AUTOSAR XML (schema 00046)
package /MICROSAR/IoHwAb_swc/ComponentTypes
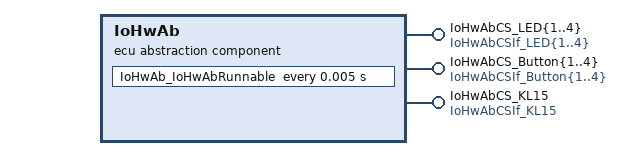
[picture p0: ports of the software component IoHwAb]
  ecu abstraction sw component type IoHwAb
    9 x provide port:
      IoHwAbCS_LED{1..4}: provided-interface=IoHwAbCSIf_LED{1..4}
      IoHwAbCS_Button{1..4}: provided-interface=IoHwAbCSIf_Button{1..4}
      IoHwAbCS_KL15: provided-interface=IoHwAbCSIf_KL15
    behavior IoHwAbInternalBehavior: handle-termination-and-restart=NO-SUPPORT
      13 x operation invoked event:
        OpEventIoHwAb_IoHwAbCS_LED1_IoHwAbOp_LED1_Write_IoHwAbOp_LED1_Write_IoHwAbCS_LED1: start-on-event=IoHwAb_IoHwAbCS_LED1_IoHwAbOp_LED1_Write, operation=IoHwAbCS_LED1.IoHwAbOp_LED1_Write
        OpEventIoHwAb_IoHwAbCS_LED1_IoHwAbOp_LED1_Read_IoHwAbOp_LED1_Read_IoHwAbCS_LED1: start-on-event=IoHwAb_IoHwAbCS_LED1_IoHwAbOp_LED1_Read, operation=IoHwAbCS_LED1.IoHwAbOp_LED1_Read
        OpEventIoHwAb_IoHwAbCS_LED2_IoHwAbOp_LED2_Write_IoHwAbOp_LED2_Write_IoHwAbCS_LED2: start-on-event=IoHwAb_IoHwAbCS_LED2_IoHwAbOp_LED2_Write, operation=IoHwAbCS_LED2.IoHwAbOp_LED2_Write
        OpEventIoHwAb_IoHwAbCS_LED2_IoHwAbOp_LED2_Read_IoHwAbOp_LED2_Read_IoHwAbCS_LED2: start-on-event=IoHwAb_IoHwAbCS_LED2_IoHwAbOp_LED2_Read, operation=IoHwAbCS_LED2.IoHwAbOp_LED2_Read
        OpEventIoHwAb_IoHwAbCS_LED3_IoHwAbOp_LED3_Write_IoHwAbOp_LED3_Write_IoHwAbCS_LED3: start-on-event=IoHwAb_IoHwAbCS_LED3_IoHwAbOp_LED3_Write, operation=IoHwAbCS_LED3.IoHwAbOp_LED3_Write
        OpEventIoHwAb_IoHwAbCS_LED3_IoHwAbOp_LED3_Read_IoHwAbOp_LED3_Read_IoHwAbCS_LED3: start-on-event=IoHwAb_IoHwAbCS_LED3_IoHwAbOp_LED3_Read, operation=IoHwAbCS_LED3.IoHwAbOp_LED3_Read
        OpEventIoHwAb_IoHwAbCS_LED4_IoHwAbOp_LED4_Write_IoHwAbOp_LED4_Write_IoHwAbCS_LED4: start-on-event=IoHwAb_IoHwAbCS_LED4_IoHwAbOp_LED4_Write, operation=IoHwAbCS_LED4.IoHwAbOp_LED4_Write
        OpEventIoHwAb_IoHwAbCS_LED4_IoHwAbOp_LED4_Read_IoHwAbOp_LED4_Read_IoHwAbCS_LED4: start-on-event=IoHwAb_IoHwAbCS_LED4_IoHwAbOp_LED4_Read, operation=IoHwAbCS_LED4.IoHwAbOp_LED4_Read
        OpEventIoHwAb_IoHwAbCS_Button{1..4}_IoHwAbOp_Button{1..4}_Read_IoHwAbOp_Button{1..4}_Read_IoHwAbCS_Button{1..4}: start-on-event=IoHwAb_IoHwAbCS_Button{1..4}_IoHwAbOp_Button{1..4}_Read, operation=IoHwAbCS_Button{1..4}.IoHwAbOp_Button{1..4}_Read
        OpEventIoHwAb_IoHwAbCS_KL15_IoHwAbOp_KL15_Read_IoHwAbOp_KL15_Read_IoHwAbCS_KL15: start-on-event=IoHwAb_IoHwAbCS_KL15_IoHwAbOp_KL15_Read, operation=IoHwAbCS_KL15.IoHwAbOp_KL15_Read
      timing event Timer_IoHwAb_IoHwAbRunnable: start-on-event=IoHwAb_IoHwAbRunnable, period=0.005
      port-api-options:
        enable-take-address=true, indirect-api=false, port=IoHwAbCS_LED{1..4}
        enable-take-address=true, indirect-api=false, port=IoHwAbCS_Button{1..4}
        enable-take-address=true, indirect-api=false, port=IoHwAbCS_KL15
      14 x runnable, all with can-be-invoked-concurrently=true:
        IoHwAb_IoHwAbCS_LED1_IoHwAbOp_LED1_Write  # Runnable Entity for calling the Operation 'IoHwAbOp_LED1_Write' of the Client/Server Port Prototype 'IoHwAbCS_LED1'.
        IoHwAb_IoHwAbCS_LED1_IoHwAbOp_LED1_Read  # Runnable Entity for calling the Operation 'IoHwAbOp_LED1_Read' of the Client/Server Port Prototype 'IoHwAbCS_LED1'.
        IoHwAb_IoHwAbCS_LED2_IoHwAbOp_LED2_Write  # Runnable Entity for calling the Operation 'IoHwAbOp_LED2_Write' of the Client/Server Port Prototype 'IoHwAbCS_LED2'.
        IoHwAb_IoHwAbCS_LED2_IoHwAbOp_LED2_Read  # Runnable Entity for calling the Operation 'IoHwAbOp_LED2_Read' of the Client/Server Port Prototype 'IoHwAbCS_LED2'.
        IoHwAb_IoHwAbCS_LED3_IoHwAbOp_LED3_Write  # Runnable Entity for calling the Operation 'IoHwAbOp_LED3_Write' of the Client/Server Port Prototype 'IoHwAbCS_LED3'.
        IoHwAb_IoHwAbCS_LED3_IoHwAbOp_LED3_Read  # Runnable Entity for calling the Operation 'IoHwAbOp_LED3_Read' of the Client/Server Port Prototype 'IoHwAbCS_LED3'.
        IoHwAb_IoHwAbCS_LED4_IoHwAbOp_LED4_Write  # Runnable Entity for calling the Operation 'IoHwAbOp_LED4_Write' of the Client/Server Port Prototype 'IoHwAbCS_LED4'.
        IoHwAb_IoHwAbCS_LED4_IoHwAbOp_LED4_Read  # Runnable Entity for calling the Operation 'IoHwAbOp_LED4_Read' of the Client/Server Port Prototype 'IoHwAbCS_LED4'.
        IoHwAb_IoHwAbCS_Button{1..4}_IoHwAbOp_Button{1..4}_Read  # Runnable Entity for calling the Operation 'IoHwAbOp_Button{1..4}_Read' of the Client/Server Port Prototype 'IoHwAbCS_Button{1..4}'.
        IoHwAb_IoHwAbCS_KL15_IoHwAbOp_KL15_Read  # Runnable Entity for calling the Operation 'IoHwAbOp_KL15_Read' of the Client/Server Port Prototype 'IoHwAbCS_KL15'.
        IoHwAb_IoHwAbRunnable
  swc implementation IoHwAbImplementation: programming-language=C, behavior=IoHwAbInternalBehavior
package /MICROSAR/IoHwAb_swc/Interfaces
  9 x client server interface:
    IoHwAbCSIf_Button4
      operation IoHwAbOp_Button4_Read: possible-error=IoHwAbCSIf_Button4/IoHwAbApplicationError
        arg IoHwAbOperationArgument: type=IOHWAB_BOOL, direction=OUT
      error IoHwAbApplicationError: error-code=1
    IoHwAbCSIf_Button3
      operation IoHwAbOp_Button3_Read: possible-error=IoHwAbCSIf_Button3/IoHwAbApplicationError
        arg IoHwAbOperationArgument: type=IOHWAB_BOOL, direction=OUT
      error IoHwAbApplicationError: error-code=1
    IoHwAbCSIf_Button2
      operation IoHwAbOp_Button2_Read: possible-error=IoHwAbCSIf_Button2/IoHwAbApplicationError
        arg IoHwAbOperationArgument: type=IOHWAB_BOOL, direction=OUT
      error IoHwAbApplicationError: error-code=1
    IoHwAbCSIf_Button1
      operation IoHwAbOp_Button1_Read: possible-error=IoHwAbCSIf_Button1/IoHwAbApplicationError
        arg IoHwAbOperationArgument: type=IOHWAB_BOOL, direction=OUT
      error IoHwAbApplicationError: error-code=1
    IoHwAbCSIf_LED4
      operation IoHwAbOp_LED4_Write: possible-error=IoHwAbCSIf_LED4/IoHwAbApplicationError
        arg IoHwAbOperationArgument: type=IOHWAB_BOOL, direction=IN
      operation IoHwAbOp_LED4_Read: possible-error=IoHwAbCSIf_LED4/IoHwAbApplicationError
        arg IoHwAbOperationArgument: type=IOHWAB_BOOL, direction=OUT
      error IoHwAbApplicationError: error-code=1
    IoHwAbCSIf_LED3
      operation IoHwAbOp_LED3_Write: possible-error=IoHwAbCSIf_LED3/IoHwAbApplicationError
        arg IoHwAbOperationArgument: type=IOHWAB_BOOL, direction=IN
      operation IoHwAbOp_LED3_Read: possible-error=IoHwAbCSIf_LED3/IoHwAbApplicationError
        arg IoHwAbOperationArgument: type=IOHWAB_BOOL, direction=OUT
      error IoHwAbApplicationError: error-code=1
    IoHwAbCSIf_KL15
      operation IoHwAbOp_KL15_Read: possible-error=IoHwAbCSIf_KL15/IoHwAbApplicationError
        arg IoHwAbOperationArgument: type=IOHWAB_BOOL, direction=OUT
      error IoHwAbApplicationError: error-code=1
    IoHwAbCSIf_LED2
      operation IoHwAbOp_LED2_Write: possible-error=IoHwAbCSIf_LED2/IoHwAbApplicationError
        arg IoHwAbOperationArgument: type=IOHWAB_BOOL, direction=IN
      operation IoHwAbOp_LED2_Read: possible-error=IoHwAbCSIf_LED2/IoHwAbApplicationError
        arg IoHwAbOperationArgument: type=IOHWAB_BOOL, direction=OUT
      error IoHwAbApplicationError: error-code=1
    IoHwAbCSIf_LED1
      operation IoHwAbOp_LED1_Write: possible-error=IoHwAbCSIf_LED1/IoHwAbApplicationError
        arg IoHwAbOperationArgument: type=IOHWAB_BOOL, direction=IN
      operation IoHwAbOp_LED1_Read: possible-error=IoHwAbCSIf_LED1/IoHwAbApplicationError
        arg IoHwAbOperationArgument: type=IOHWAB_BOOL, direction=OUT
      error IoHwAbApplicationError: error-code=1
package /MICROSAR/IoHwAb_swc/DataTypes
  impl type IOHWAB_BOOL: implementation-data-type=boolean
